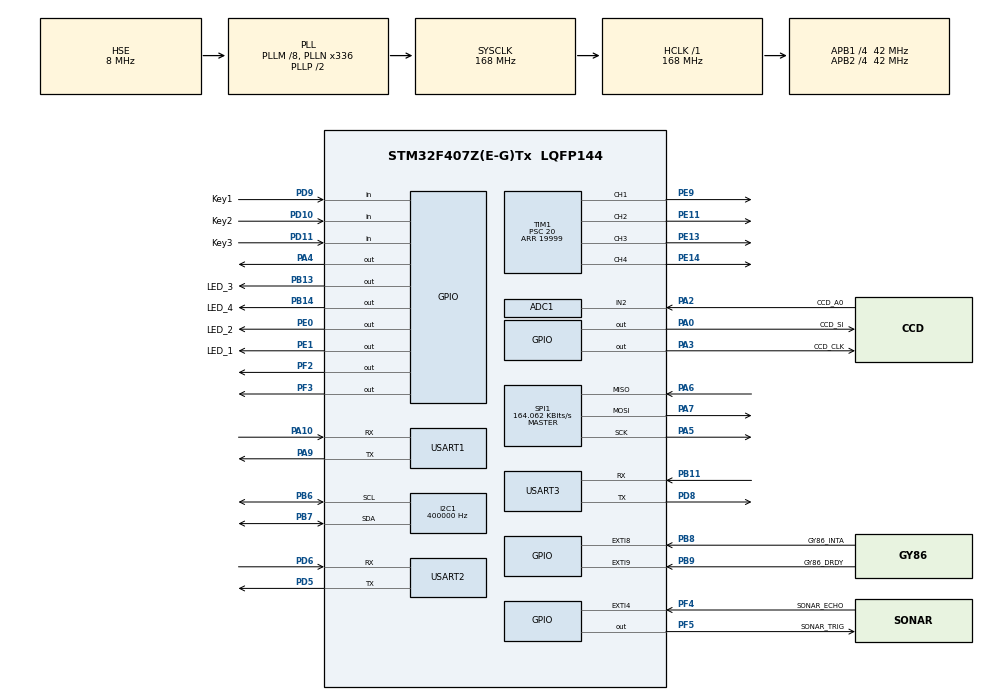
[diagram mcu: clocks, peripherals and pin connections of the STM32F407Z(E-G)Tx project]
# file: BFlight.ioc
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ADC1.Channel-6\#ChannelRegularConversion=ADC_CHANNEL_2
ADC1.ClockPrescaler=ADC_CLOCKPRESCALER_PCLK_DIV2
ADC1.NbrOfConversionFlag=1
ADC1.master=1
Dma.Request0=USART1_TX
Dma.USART1_TX.0.Channel=DMA_CHANNEL_4
Dma.USART1_TX.0.Direction=DMA_MEMORY_TO_PERIPH
Dma.USART1_TX.0.FIFOMode=DMA_FIFOMODE_DISABLE
Dma.USART1_TX.0.Instance=DMA2_Stream7
Dma.USART1_TX.0.MemDataAlignment=DMA_MDATAALIGN_BYTE
Dma.USART1_TX.0.MemInc=DMA_MINC_ENABLE
Dma.USART1_TX.0.Mode=DMA_NORMAL
Dma.USART1_TX.0.PeriphDataAlignment=DMA_PDATAALIGN_BYTE
Dma.USART1_TX.0.PeriphInc=DMA_PINC_DISABLE
Dma.USART1_TX.0.Priority=DMA_PRIORITY_LOW
I2C1.ClockSpeed=400000
I2C1.I2C_Mode=I2C_Fast
Mcu.Family=STM32F4
Mcu.Name=STM32F407Z(E-G)Tx
Mcu.Package=LQFP144
NVIC.DMA2_Stream7_IRQn=true\:10\:0\:true
NVIC.EXTI4_IRQn=true\:6\:0\:true
NVIC.EXTI9_5_IRQn=true\:5\:0\:true
NVIC.PriorityGroup=NVIC_PRIORITYGROUP_4
NVIC.TIM4_IRQn=true\:8\:0\:true
NVIC.USART1_IRQn=true\:7\:0\:true
NVIC.USART2_IRQn=true\:9\:0\:true
NVIC.USART3_IRQn=true\:4\:0\:true
PA0-WKUP.GPIO_Label=CCD_SI
PA0-WKUP.GPIO_ModeDefaultOutputPP=GPIO_MODE_OUTPUT_PP
PA0-WKUP.GPIO_PuPd=GPIO_NOPULL
PA0-WKUP.GPIO_Speed=GPIO_SPEED_HIGH
PA0-WKUP.Signal=GPIO_Output
PA10.Mode=Asynchronous
PA10.Signal=USART1_RX
PA13.Mode=JTAG(5-pin)
PA13.Signal=SYS_JTMS-SWDIO
PA14.Mode=JTAG(5-pin)
PA14.Signal=SYS_JTCK-SWCLK
PA15.Mode=JTAG(5-pin)
PA15.Signal=SYS_JTDI
PA2.GPIO_Label=CCD_A0
PA2.GPIO_Mode=GPIO_MODE_ANALOG
PA2.GPIO_PuPd=GPIO_NOPULL
PA2.Signal=ADCx_IN2
PA3.GPIO_Label=CCD_CLK
PA3.GPIO_ModeDefaultOutputPP=GPIO_MODE_OUTPUT_PP
PA3.GPIO_PuPd=GPIO_NOPULL
PA3.GPIO_Speed=GPIO_SPEED_HIGH
PA3.Signal=GPIO_Output
PA4.Signal=GPIO_Output
PA5.Mode=Full_Duplex_Master
PA5.Signal=SPI1_SCK
PA6.Mode=Full_Duplex_Master
PA6.Signal=SPI1_MISO
PA7.Mode=Full_Duplex_Master
PA7.Signal=SPI1_MOSI
PA9.Mode=Asynchronous
PA9.Signal=USART1_TX
PB11.Mode=Asynchronous
PB11.Signal=USART3_RX
PB13.GPIO_Label=LED_3
PB13.GPIO_ModeDefaultOutputPP=GPIO_MODE_OUTPUT_PP
PB13.GPIO_PuPd=GPIO_NOPULL
PB13.GPIO_Speed=GPIO_SPEED_LOW
PB13.Signal=GPIO_Output
PB14.GPIO_Label=LED_4
PB14.GPIO_ModeDefaultOutputPP=GPIO_MODE_OUTPUT_PP
PB14.GPIO_PuPd=GPIO_NOPULL
PB14.GPIO_Speed=GPIO_SPEED_LOW
PB14.Signal=GPIO_Output
PB3.Mode=JTAG(5-pin)
PB3.Signal=SYS_JTDO-SWO
PB4.Mode=JTAG(5-pin)
PB4.Signal=SYS_JTRST
PB6.Mode=I2C
PB6.Signal=I2C1_SCL
PB7.Mode=I2C
PB7.Signal=I2C1_SDA
PB8.GPIO_Label=GY86_INTA
PB8.GPIO_ModeDefaultEXTI=GPIO_MODE_IT_FALLING
PB8.GPIO_PuPd=GPIO_NOPULL
PB8.Signal=GPXTI8
PB9.GPIO_Label=GY86_DRDY
PB9.GPIO_ModeDefaultEXTI=GPIO_MODE_IT_FALLING
PB9.GPIO_PuPd=GPIO_NOPULL
PB9.Signal=GPXTI9
PC8.Signal=S_TIM8_CH3
PC9.Signal=S_TIM8_CH4
PD10.GPIO_Label=Key2
PD10.GPIO_Mode=GPIO_MODE_INPUT
PD10.GPIO_PuPd=GPIO_PULLUP
PD10.Signal=GPIO_Input
PD11.GPIO_Label=Key3
PD11.GPIO_Mode=GPIO_MODE_INPUT
PD11.GPIO_PuPd=GPIO_PULLUP
PD11.Signal=GPIO_Input
PD5.Mode=Asynchronous
PD5.Signal=USART2_TX
PD6.Mode=Asynchronous
PD6.Signal=USART2_RX
PD8.Mode=Asynchronous
PD8.Signal=USART3_TX
PD9.GPIO_Label=Key1
PD9.GPIO_Mode=GPIO_MODE_INPUT
PD9.GPIO_PuPd=GPIO_PULLUP
PD9.Signal=GPIO_Input
PE0.GPIO_Label=LED_2
PE0.GPIO_ModeDefaultOutputPP=GPIO_MODE_OUTPUT_PP
PE0.GPIO_PuPd=GPIO_NOPULL
PE0.GPIO_Speed=GPIO_SPEED_LOW
PE0.Signal=GPIO_Output
PE1.GPIO_Label=LED_1
PE1.GPIO_ModeDefaultOutputPP=GPIO_MODE_OUTPUT_PP
PE1.GPIO_PuPd=GPIO_NOPULL
PE1.GPIO_Speed=GPIO_SPEED_LOW
PE1.Signal=GPIO_Output
PE11.Signal=S_TIM1_CH2
PE13.Signal=S_TIM1_CH3
PE14.Signal=S_TIM1_CH4
PE9.Signal=S_TIM1_CH1
PF2.Signal=GPIO_Output
PF3.Signal=GPIO_Output
PF4.GPIO_Label=SONAR_ECHO
PF4.GPIO_ModeDefaultEXTI=GPIO_MODE_IT_RISING_FALLING
PF4.GPIO_PuPd=GPIO_NOPULL
PF4.Signal=GPXTI4
PF5.GPIO_Label=SONAR_TRIG
PF5.GPIO_ModeDefaultOutputPP=GPIO_MODE_OUTPUT_PP
PF5.GPIO_PuPd=GPIO_NOPULL
PF5.GPIO_Speed=GPIO_SPEED_LOW
PF5.Signal=GPIO_Output
PH0-OSC_IN.Mode=HSE-External-Oscillator
PH0-OSC_IN.Signal=RCC_OSC_IN
PH1-OSC_OUT.Mode=HSE-External-Oscillator
PH1-OSC_OUT.Signal=RCC_OSC_OUT
ProjectManager.TargetToolchain=MDK-ARM V5
RCC.48MHZClocksFreq_Value=48000000
RCC.AHBFreq_Value=168000000
RCC.APB1CLKDivider=RCC_HCLK_DIV4
RCC.APB1Freq_Value=42000000
RCC.APB1TimFreq_Value=84000000
RCC.APB2CLKDivider=RCC_HCLK_DIV4
RCC.APB2Freq_Value=42000000
RCC.APB2TimFreq_Value=84000000
RCC.CortexFreq_Value=168000000
RCC.HCLKFreq_Value=168000000
RCC.HSE_VALUE=8000000
RCC.HSI_VALUE=16000000
RCC.LSE_VALUE=32768
RCC.PLLM=8
RCC.PLLN=336
RCC.PLLQ=7
RCC.PLLSourceVirtual=RCC_PLLSOURCE_HSE
RCC.SYSCLKFreq_VALUE=168000000
RCC.SYSCLKSource=RCC_SYSCLKSOURCE_PLLCLK
RCC.VCOOutputFreq_Value=336000000
SH.ADCx_IN2.0=ADC1_IN2,IN2
SH.S_TIM1_CH1.0=TIM1_CH1,PWM Generation1 CH1
SH.S_TIM1_CH2.0=TIM1_CH2,PWM Generation2 CH2
SH.S_TIM1_CH3.0=TIM1_CH3,PWM Generation3 CH3
SH.S_TIM1_CH4.0=TIM1_CH4,PWM Generation4 CH4
SH.S_TIM8_CH3.0=TIM8_CH3
SH.S_TIM8_CH4.0=TIM8_CH4
SPI1.BaudRatePrescaler=SPI_BAUDRATEPRESCALER_256
SPI1.CLKPhase=SPI_PHASE_2EDGE
SPI1.CLKPolarity=SPI_POLARITY_HIGH
SPI1.CalculateBaudRate=164.062 KBits/s
SPI1.Mode=SPI_MODE_MASTER
TIM1.Channel-PWM\ Generation2\ CH2=TIM_CHANNEL_2
TIM1.Channel-PWM\ Generation3\ CH3=TIM_CHANNEL_3
TIM1.Channel-PWM\ Generation4\ CH4=TIM_CHANNEL_4
TIM1.Period=19999
TIM1.Prescaler=20
TIM4.Period=65535
TIM4.Prescaler=335
TIM6.Period=65535
TIM6.Prescaler=83
VP_TIM4_VS_ClockSourceINT.Mode=Internal
VP_TIM6_VS_ClockSourceINT.Mode=Enable_Timer

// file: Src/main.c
/**
  ******************************************************************************
  * File Name          : main.c
  * Description        : Main program body
  ******************************************************************************
  *
  * COPYRIGHT(c) 2015 STMicroelectronics
  *
  * Redistribution and use in source and binary forms, with or without modification,
  * are permitted provided that the following conditions are met:
  *   1. Redistributions of source code must retain the above copyright notice,
  *      this list of conditions and the following disclaimer.
  *   2. Redistributions in binary form must reproduce the above copyright notice,
  *      this list of conditions and the following disclaimer in the documentation
  *      and/or other materials provided with the distribution.
  *   3. Neither the name of STMicroelectronics nor the names of its contributors
  *      may be used to endorse or promote products derived from this software
  *      without specific prior written permission.
  *
  * THIS SOFTWARE IS PROVIDED BY THE COPYRIGHT HOLDERS AND CONTRIBUTORS "AS IS"
  * AND ANY EXPRESS OR IMPLIED WARRANTIES, INCLUDING, BUT NOT LIMITED TO, THE
  * IMPLIED WARRANTIES OF MERCHANTABILITY AND FITNESS FOR A PARTICULAR PURPOSE ARE
  * DISCLAIMED. IN NO EVENT SHALL THE COPYRIGHT HOLDER OR CONTRIBUTORS BE LIABLE
  * FOR ANY DIRECT, INDIRECT, INCIDENTAL, SPECIAL, EXEMPLARY, OR CONSEQUENTIAL
  * DAMAGES (INCLUDING, BUT NOT LIMITED TO, PROCUREMENT OF SUBSTITUTE GOODS OR
  * SERVICES; LOSS OF USE, DATA, OR PROFITS; OR BUSINESS INTERRUPTION) HOWEVER
  * CAUSED AND ON ANY THEORY OF LIABILITY, WHETHER IN CONTRACT, STRICT LIABILITY,
  * OR TORT (INCLUDING NEGLIGENCE OR OTHERWISE) ARISING IN ANY WAY OUT OF THE USE
  * OF THIS SOFTWARE, EVEN IF ADVISED OF THE POSSIBILITY OF SUCH DAMAGE.
  *
  ******************************************************************************
  */
#include "stm32f4xx_hal.h"

/* USER CODE BEGIN Includes */
#include "Fly/FlyMain.h"
/* USER CODE END Includes */

ADC_HandleTypeDef hadc1;

I2C_HandleTypeDef hi2c1;

SPI_HandleTypeDef hspi1;

TIM_HandleTypeDef htim1;
TIM_HandleTypeDef htim4;
TIM_HandleTypeDef htim6;

UART_HandleTypeDef huart1;
UART_HandleTypeDef huart2;
UART_HandleTypeDef huart3;
DMA_HandleTypeDef hdma_usart1_tx;

void SystemClock_Config(void);
static void MX_GPIO_Init(void);
static void MX_DMA_Init(void);
static void MX_ADC1_Init(void);
static void MX_I2C1_Init(void);
static void MX_SPI1_Init(void);
static void MX_TIM1_Init(void);
static void MX_TIM4_Init(void);
static void MX_TIM6_Init(void);
static void MX_USART1_UART_Init(void);
static void MX_USART2_UART_Init(void);
static void MX_USART3_UART_Init(void);

int main(void)
{

  /* MCU Configuration----------------------------------------------------------*/

  /* Reset of all peripherals, Initializes the Flash interface and the Systick. */
  HAL_Init();

  /* Configure the system clock */
  SystemClock_Config();

  /* Initialize all configured peripherals */
  MX_GPIO_Init();
  MX_DMA_Init();
  MX_ADC1_Init();
  MX_I2C1_Init();
  MX_SPI1_Init();
  MX_TIM1_Init();
  MX_TIM4_Init();
  MX_TIM6_Init();
  MX_USART1_UART_Init();
  MX_USART2_UART_Init();
  MX_USART3_UART_Init();

  /* Infinite loop */
  while (1)
  {

  /* USER CODE BEGIN 3 */

  FlyMain();
  }
  /* USER CODE END 3 */

}

/** System Clock Configuration
*/
void SystemClock_Config(void)
{

  RCC_OscInitTypeDef RCC_OscInitStruct;
  RCC_ClkInitTypeDef RCC_ClkInitStruct;

  __PWR_CLK_ENABLE();

  __HAL_PWR_VOLTAGESCALING_CONFIG(PWR_REGULATOR_VOLTAGE_SCALE1);

  RCC_OscInitStruct.OscillatorType = RCC_OSCILLATORTYPE_HSE;
  RCC_OscInitStruct.HSEState = RCC_HSE_ON;
  RCC_OscInitStruct.PLL.PLLState = RCC_PLL_ON;
  RCC_OscInitStruct.PLL.PLLSource = RCC_PLLSOURCE_HSE;
  RCC_OscInitStruct.PLL.PLLM = 8;
  RCC_OscInitStruct.PLL.PLLN = 336;
  RCC_OscInitStruct.PLL.PLLP = RCC_PLLP_DIV2;
  RCC_OscInitStruct.PLL.PLLQ = 7;
  HAL_RCC_OscConfig(&RCC_OscInitStruct);

  RCC_ClkInitStruct.ClockType = RCC_CLOCKTYPE_SYSCLK|RCC_CLOCKTYPE_PCLK1
                              |RCC_CLOCKTYPE_PCLK2;
  RCC_ClkInitStruct.SYSCLKSource = RCC_SYSCLKSOURCE_PLLCLK;
  RCC_ClkInitStruct.AHBCLKDivider = RCC_SYSCLK_DIV1;
  RCC_ClkInitStruct.APB1CLKDivider = RCC_HCLK_DIV4;
  RCC_ClkInitStruct.APB2CLKDivider = RCC_HCLK_DIV4;
  HAL_RCC_ClockConfig(&RCC_ClkInitStruct, FLASH_LATENCY_5);

  HAL_SYSTICK_Config(HAL_RCC_GetHCLKFreq()/1000);

  HAL_SYSTICK_CLKSourceConfig(SYSTICK_CLKSOURCE_HCLK);

}

/* ADC1 init function */
void MX_ADC1_Init(void)
{

  ADC_ChannelConfTypeDef sConfig;

    /**Configure the global features of the ADC (Clock, Resolution, Data Alignment and number of conversion)
    */
  hadc1.Instance = ADC1;
  hadc1.Init.ClockPrescaler = ADC_CLOCKPRESCALER_PCLK_DIV2;
  hadc1.Init.Resolution = ADC_RESOLUTION12b;
  hadc1.Init.ScanConvMode = DISABLE;
  hadc1.Init.ContinuousConvMode = DISABLE;
  hadc1.Init.DiscontinuousConvMode = DISABLE;
  hadc1.Init.ExternalTrigConvEdge = ADC_EXTERNALTRIGCONVEDGE_NONE;
  hadc1.Init.DataAlign = ADC_DATAALIGN_RIGHT;
  hadc1.Init.NbrOfConversion = 1;
  hadc1.Init.DMAContinuousRequests = DISABLE;
  hadc1.Init.EOCSelection = EOC_SINGLE_CONV;
  HAL_ADC_Init(&hadc1);

    /**Configure for the selected ADC regular channel its corresponding rank in the sequencer and its sample time.
    */
  sConfig.Channel = ADC_CHANNEL_2;
  sConfig.Rank = 1;
  sConfig.SamplingTime = ADC_SAMPLETIME_3CYCLES;
  HAL_ADC_ConfigChannel(&hadc1, &sConfig);

}

/* I2C1 init function */
void MX_I2C1_Init(void)
{

  hi2c1.Instance = I2C1;
  hi2c1.Init.ClockSpeed = 400000;
  hi2c1.Init.DutyCycle = I2C_DUTYCYCLE_2;
  hi2c1.Init.OwnAddress1 = 0;
  hi2c1.Init.AddressingMode = I2C_ADDRESSINGMODE_7BIT;
  hi2c1.Init.DualAddressMode = I2C_DUALADDRESS_DISABLED;
  hi2c1.Init.OwnAddress2 = 0;
  hi2c1.Init.GeneralCallMode = I2C_GENERALCALL_DISABLED;
  hi2c1.Init.NoStretchMode = I2C_NOSTRETCH_DISABLED;
  HAL_I2C_Init(&hi2c1);

}

/* SPI1 init function */
void MX_SPI1_Init(void)
{

  hspi1.Instance = SPI1;
  hspi1.Init.Mode = SPI_MODE_MASTER;
  hspi1.Init.Direction = SPI_DIRECTION_2LINES;
  hspi1.Init.DataSize = SPI_DATASIZE_8BIT;
  hspi1.Init.CLKPolarity = SPI_POLARITY_HIGH;
  hspi1.Init.CLKPhase = SPI_PHASE_2EDGE;
  hspi1.Init.NSS = SPI_NSS_SOFT;
  hspi1.Init.BaudRatePrescaler = SPI_BAUDRATEPRESCALER_256;
  hspi1.Init.FirstBit = SPI_FIRSTBIT_MSB;
  hspi1.Init.TIMode = SPI_TIMODE_DISABLED;
  hspi1.Init.CRCCalculation = SPI_CRCCALCULATION_DISABLED;
  hspi1.Init.CRCPolynomial = 10;
  HAL_SPI_Init(&hspi1);

}

/* TIM1 init function */
void MX_TIM1_Init(void)
{

  TIM_MasterConfigTypeDef sMasterConfig;
  TIM_BreakDeadTimeConfigTypeDef sBreakDeadTimeConfig;
  TIM_OC_InitTypeDef sConfigOC;

  htim1.Instance = TIM1;
  htim1.Init.Prescaler = 20;
  htim1.Init.CounterMode = TIM_COUNTERMODE_UP;
  htim1.Init.Period = 19999;
  htim1.Init.ClockDivision = TIM_CLOCKDIVISION_DIV1;
  htim1.Init.RepetitionCounter = 0;
  HAL_TIM_PWM_Init(&htim1);

  sMasterConfig.MasterOutputTrigger = TIM_TRGO_RESET;
  sMasterConfig.MasterSlaveMode = TIM_MASTERSLAVEMODE_DISABLE;
  HAL_TIMEx_MasterConfigSynchronization(&htim1, &sMasterConfig);

  sBreakDeadTimeConfig.OffStateRunMode = TIM_OSSR_DISABLE;
  sBreakDeadTimeConfig.OffStateIDLEMode = TIM_OSSI_DISABLE;
  sBreakDeadTimeConfig.LockLevel = TIM_LOCKLEVEL_OFF;
  sBreakDeadTimeConfig.DeadTime = 0;
  sBreakDeadTimeConfig.BreakState = TIM_BREAK_DISABLE;
  sBreakDeadTimeConfig.BreakPolarity = TIM_BREAKPOLARITY_HIGH;
  sBreakDeadTimeConfig.AutomaticOutput = TIM_AUTOMATICOUTPUT_DISABLE;
  HAL_TIMEx_ConfigBreakDeadTime(&htim1, &sBreakDeadTimeConfig);

  sConfigOC.OCMode = TIM_OCMODE_PWM1;
  sConfigOC.Pulse = 0;
  sConfigOC.OCPolarity = TIM_OCPOLARITY_HIGH;
  sConfigOC.OCNPolarity = TIM_OCNPOLARITY_HIGH;
  sConfigOC.OCFastMode = TIM_OCFAST_DISABLE;
  sConfigOC.OCIdleState = TIM_OCIDLESTATE_RESET;
  sConfigOC.OCNIdleState = TIM_OCNIDLESTATE_RESET;
  HAL_TIM_PWM_ConfigChannel(&htim1, &sConfigOC, TIM_CHANNEL_1);

  HAL_TIM_PWM_ConfigChannel(&htim1, &sConfigOC, TIM_CHANNEL_2);

  HAL_TIM_PWM_ConfigChannel(&htim1, &sConfigOC, TIM_CHANNEL_3);

  HAL_TIM_PWM_ConfigChannel(&htim1, &sConfigOC, TIM_CHANNEL_4);

}

/* TIM4 init function */
void MX_TIM4_Init(void)
{

  TIM_ClockConfigTypeDef sClockSourceConfig;
  TIM_MasterConfigTypeDef sMasterConfig;

  htim4.Instance = TIM4;
  htim4.Init.Prescaler = 335;
  htim4.Init.CounterMode = TIM_COUNTERMODE_UP;
  htim4.Init.Period = 65535;
  htim4.Init.ClockDivision = TIM_CLOCKDIVISION_DIV1;
  HAL_TIM_Base_Init(&htim4);

  sClockSourceConfig.ClockSource = TIM_CLOCKSOURCE_INTERNAL;
  HAL_TIM_ConfigClockSource(&htim4, &sClockSourceConfig);

  sMasterConfig.MasterOutputTrigger = TIM_TRGO_RESET;
  sMasterConfig.MasterSlaveMode = TIM_MASTERSLAVEMODE_DISABLE;
  HAL_TIMEx_MasterConfigSynchronization(&htim4, &sMasterConfig);

}

/* TIM6 init function */
void MX_TIM6_Init(void)
{

  TIM_MasterConfigTypeDef sMasterConfig;

  htim6.Instance = TIM6;
  htim6.Init.Prescaler = 83;
  htim6.Init.CounterMode = TIM_COUNTERMODE_UP;
  htim6.Init.Period = 65535;
  HAL_TIM_Base_Init(&htim6);

  sMasterConfig.MasterOutputTrigger = TIM_TRGO_RESET;
  sMasterConfig.MasterSlaveMode = TIM_MASTERSLAVEMODE_DISABLE;
  HAL_TIMEx_MasterConfigSynchronization(&htim6, &sMasterConfig);

}

/* USART1 init function */
void MX_USART1_UART_Init(void)
{

  huart1.Instance = USART1;
  huart1.Init.BaudRate = 115200;
  huart1.Init.WordLength = UART_WORDLENGTH_8B;
  huart1.Init.StopBits = UART_STOPBITS_1;
  huart1.Init.Parity = UART_PARITY_NONE;
  huart1.Init.Mode = UART_MODE_TX_RX;
  huart1.Init.HwFlowCtl = UART_HWCONTROL_NONE;
  huart1.Init.OverSampling = UART_OVERSAMPLING_16;
  HAL_UART_Init(&huart1);

}

/* USART2 init function */
void MX_USART2_UART_Init(void)
{

  huart2.Instance = USART2;
  huart2.Init.BaudRate = 115200;
  huart2.Init.WordLength = UART_WORDLENGTH_8B;
  huart2.Init.StopBits = UART_STOPBITS_1;
  huart2.Init.Parity = UART_PARITY_NONE;
  huart2.Init.Mode = UART_MODE_TX_RX;
  huart2.Init.HwFlowCtl = UART_HWCONTROL_NONE;
  huart2.Init.OverSampling = UART_OVERSAMPLING_16;
  HAL_UART_Init(&huart2);

}

/* USART3 init function */
void MX_USART3_UART_Init(void)
{

  huart3.Instance = USART3;
  huart3.Init.BaudRate = 115200;
  huart3.Init.WordLength = UART_WORDLENGTH_8B;
  huart3.Init.StopBits = UART_STOPBITS_1;
  huart3.Init.Parity = UART_PARITY_NONE;
  huart3.Init.Mode = UART_MODE_TX_RX;
  huart3.Init.HwFlowCtl = UART_HWCONTROL_NONE;
  huart3.Init.OverSampling = UART_OVERSAMPLING_16;
  HAL_UART_Init(&huart3);

}

void MX_DMA_Init(void)
{
  /* DMA controller clock enable */
  __DMA2_CLK_ENABLE();

  /* DMA interrupt init */
  HAL_NVIC_SetPriority(DMA2_Stream7_IRQn, 10, 0);
  HAL_NVIC_EnableIRQ(DMA2_Stream7_IRQn);

}

/** Configure pins as
        * Analog
        * Input
        * Output
        * EVENT_OUT
        * EXTI
     PC8   ------> S_TIM8_CH3
     PC9   ------> S_TIM8_CH4
*/
void MX_GPIO_Init(void)
{

  GPIO_InitTypeDef GPIO_InitStruct;

  /* GPIO Ports Clock Enable */
  __GPIOF_CLK_ENABLE();
  __GPIOH_CLK_ENABLE();
  __GPIOA_CLK_ENABLE();
  __GPIOE_CLK_ENABLE();
  __GPIOB_CLK_ENABLE();
  __GPIOD_CLK_ENABLE();
  __GPIOC_CLK_ENABLE();

  /*Configure GPIO pins : PF2 PF3 PF5 */
  GPIO_InitStruct.Pin = GPIO_PIN_2|GPIO_PIN_3|GPIO_PIN_5;
  GPIO_InitStruct.Mode = GPIO_MODE_OUTPUT_PP;
  GPIO_InitStruct.Pull = GPIO_NOPULL;
  GPIO_InitStruct.Speed = GPIO_SPEED_LOW;
  HAL_GPIO_Init(GPIOF, &GPIO_InitStruct);

  /*Configure GPIO pin : PF4 */
  GPIO_InitStruct.Pin = GPIO_PIN_4;
  GPIO_InitStruct.Mode = GPIO_MODE_IT_RISING_FALLING;
  GPIO_InitStruct.Pull = GPIO_NOPULL;
  HAL_GPIO_Init(GPIOF, &GPIO_InitStruct);

  /*Configure GPIO pins : PA0 PA3 */
  GPIO_InitStruct.Pin = GPIO_PIN_0|GPIO_PIN_3;
  GPIO_InitStruct.Mode = GPIO_MODE_OUTPUT_PP;
  GPIO_InitStruct.Pull = GPIO_NOPULL;
  GPIO_InitStruct.Speed = GPIO_SPEED_HIGH;
  HAL_GPIO_Init(GPIOA, &GPIO_InitStruct);

  /*Configure GPIO pin : PA4 */
  GPIO_InitStruct.Pin = GPIO_PIN_4;
  GPIO_InitStruct.Mode = GPIO_MODE_OUTPUT_PP;
  GPIO_InitStruct.Pull = GPIO_NOPULL;
  GPIO_InitStruct.Speed = GPIO_SPEED_LOW;
  HAL_GPIO_Init(GPIOA, &GPIO_InitStruct);

  /*Configure GPIO pins : PB13 PB14 */
  GPIO_InitStruct.Pin = GPIO_PIN_13|GPIO_PIN_14;
  GPIO_InitStruct.Mode = GPIO_MODE_OUTPUT_PP;
  GPIO_InitStruct.Pull = GPIO_NOPULL;
  GPIO_InitStruct.Speed = GPIO_SPEED_LOW;
  HAL_GPIO_Init(GPIOB, &GPIO_InitStruct);

  /*Configure GPIO pins : PD9 PD10 PD11 */
  GPIO_InitStruct.Pin = GPIO_PIN_9|GPIO_PIN_10|GPIO_PIN_11;
  GPIO_InitStruct.Mode = GPIO_MODE_INPUT;
  GPIO_InitStruct.Pull = GPIO_PULLUP;
  HAL_GPIO_Init(GPIOD, &GPIO_InitStruct);

  /*Configure GPIO pins : PC8 PC9 */
  GPIO_InitStruct.Pin = GPIO_PIN_8|GPIO_PIN_9;
  GPIO_InitStruct.Mode = GPIO_MODE_AF_PP;
  GPIO_InitStruct.Pull = GPIO_NOPULL;
  GPIO_InitStruct.Speed = GPIO_SPEED_LOW;
  GPIO_InitStruct.Alternate = GPIO_AF3_TIM8;
  HAL_GPIO_Init(GPIOC, &GPIO_InitStruct);

  /*Configure GPIO pins : PB8 PB9 */
  GPIO_InitStruct.Pin = GPIO_PIN_8|GPIO_PIN_9;
  GPIO_InitStruct.Mode = GPIO_MODE_IT_FALLING;
  GPIO_InitStruct.Pull = GPIO_NOPULL;
  HAL_GPIO_Init(GPIOB, &GPIO_InitStruct);

  /*Configure GPIO pins : PE0 PE1 */
  GPIO_InitStruct.Pin = GPIO_PIN_0|GPIO_PIN_1;
  GPIO_InitStruct.Mode = GPIO_MODE_OUTPUT_PP;
  GPIO_InitStruct.Pull = GPIO_NOPULL;
  GPIO_InitStruct.Speed = GPIO_SPEED_LOW;
  HAL_GPIO_Init(GPIOE, &GPIO_InitStruct);

  /* EXTI interrupt init*/
  HAL_NVIC_SetPriority(EXTI4_IRQn, 6, 0);
  HAL_NVIC_EnableIRQ(EXTI4_IRQn);

  HAL_NVIC_SetPriority(EXTI9_5_IRQn, 5, 0);
  HAL_NVIC_EnableIRQ(EXTI9_5_IRQn);

}

/************************ (C) COPYRIGHT STMicroelectronics *****END OF FILE****/
